VERSION "1.0"

NS_ :

BS_:

BU_: BRK BC

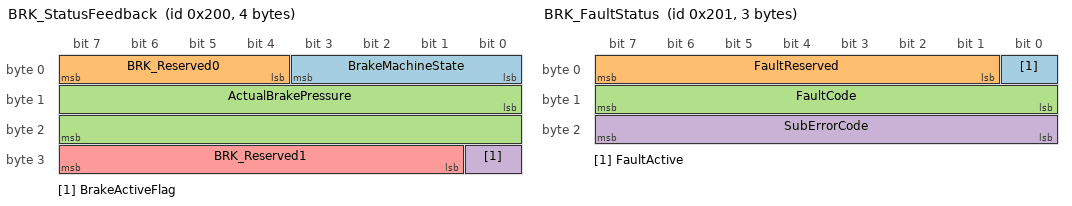
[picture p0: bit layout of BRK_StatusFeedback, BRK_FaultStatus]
BO_ 512 BRK_StatusFeedback: 4 BRK
 SG_ BrakeMachineState : 0|4@1+ (1,0) [0|4] "" BC
 SG_ BRK_Reserved0 : 4|4@1+ (1,0) [0|15] "" BC
 SG_ ActualBrakePressure : 8|16@1+ (0.1,0) [0|120] "psi" BC
 SG_ BrakeActiveFlag : 24|1@1+ (1,0) [0|1] "" BC
 SG_ BRK_Reserved1 : 25|7@1+ (1,0) [0|127] "" BC

BO_ 513 BRK_FaultStatus: 3 BRK
 SG_ FaultActive : 0|1@1+ (1,0) [0|1] "" BC
 SG_ FaultReserved : 1|7@1+ (1,0) [0|127] "" BC
 SG_ FaultCode : 8|8@1+ (1,0) [0|255] "" BC
 SG_ SubErrorCode : 16|8@1+ (1,0) [0|255] "hex" BC

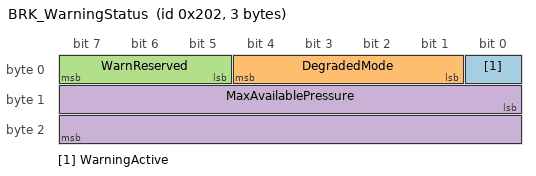
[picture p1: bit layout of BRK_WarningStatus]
BO_ 514 BRK_WarningStatus: 3 BRK
 SG_ WarningActive : 0|1@1+ (1,0) [0|1] "" BC
 SG_ DegradedMode : 1|4@1+ (1,0) [0|15] "" BC
 SG_ WarnReserved : 5|3@1+ (1,0) [0|7] "" BC
 SG_ MaxAvailablePressure : 8|16@1+ (0.1,0) [0|120] "psi" BC

VAL_ 512 BrakeMachineState 0 "wakeup" 1 "checks" 2 "ready" 3 "braking" 4 "fault" ;
VAL_ 512 BrakeActiveFlag 0 "Inactive" 1 "Active" ;
VAL_ 513 FaultActive 0 "Normal" 1 "FaultPresent" ;
VAL_ 513 FaultCode 0 "NO_FAULT" 1 "SENSOR_FAULT" 2 "ACTUATOR_FAULT" 3 "COMMS_TIMEOUT" 4 "SELFTEST_FAIL" 5 "UNDERPRESSURE" 6 "OVERPRESSURE" ;
VAL_ 514 WarningActive 0 "Normal" 1 "WarningActive" ;
VAL_ 514 DegradedMode 0 "NONE" 1 "REDUCED_CAPACITY" 2 "OVERHEATED_DERATING" 3 "SLOW_RESPONSE" 4 "BACKUP_CIRCUIT" ;
